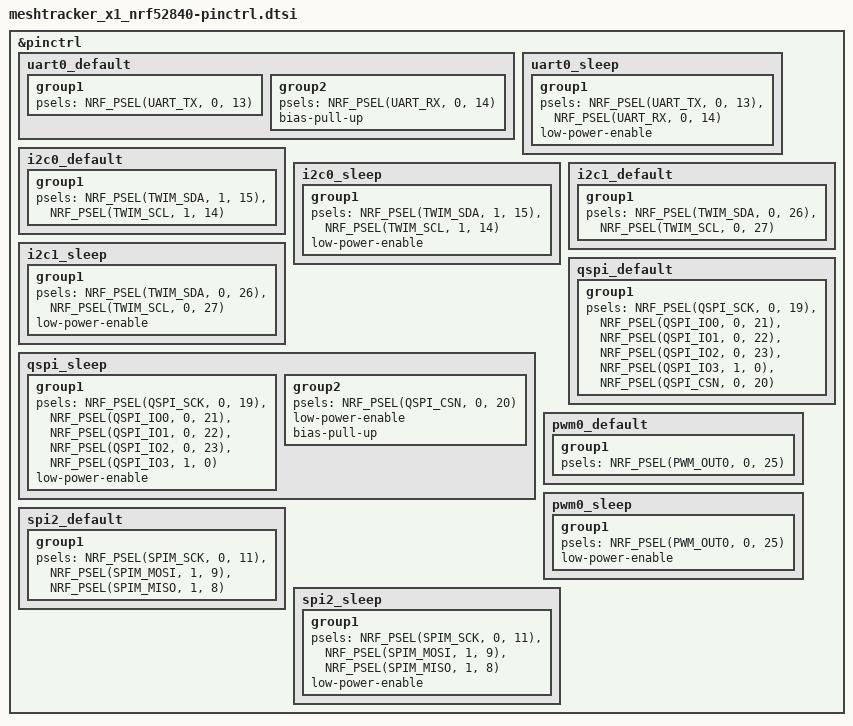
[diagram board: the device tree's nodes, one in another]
/*
 * Seeed SenseCAP MeshTracker X1 - Pin Control
 * Copyright (c) 2026 ZephCore
 * SPDX-License-Identifier: MIT
 */

&pinctrl {
	/* GNSS UART - Airoha dual-band L1+L5 at 115200 baud */
	uart0_default: uart0_default {
		group1 {
			psels = <NRF_PSEL(UART_TX, 0, 13)>;
		};
		group2 {
			psels = <NRF_PSEL(UART_RX, 0, 14)>;
			bias-pull-up;
		};
	};

	uart0_sleep: uart0_sleep {
		group1 {
			psels = <NRF_PSEL(UART_TX, 0, 13)>,
			        <NRF_PSEL(UART_RX, 0, 14)>;
			low-power-enable;
		};
	};

	/* I2C0 - SPA06 barometer + DRV2605L haptic driver */
	i2c0_default: i2c0_default {
		group1 {
			psels = <NRF_PSEL(TWIM_SDA, 1, 15)>,
			        <NRF_PSEL(TWIM_SCL, 1, 14)>;
		};
	};

	i2c0_sleep: i2c0_sleep {
		group1 {
			psels = <NRF_PSEL(TWIM_SDA, 1, 15)>,
			        <NRF_PSEL(TWIM_SCL, 1, 14)>;
			low-power-enable;
		};
	};

	/* I2C1 - YSN8900 RTC on its own bus */
	i2c1_default: i2c1_default {
		group1 {
			psels = <NRF_PSEL(TWIM_SDA, 0, 26)>,
			        <NRF_PSEL(TWIM_SCL, 0, 27)>;
		};
	};

	i2c1_sleep: i2c1_sleep {
		group1 {
			psels = <NRF_PSEL(TWIM_SDA, 0, 26)>,
			        <NRF_PSEL(TWIM_SCL, 0, 27)>;
			low-power-enable;
		};
	};

	/* QSPI - GD25Q64E 8MB flash */
	qspi_default: qspi_default {
		group1 {
			psels = <NRF_PSEL(QSPI_SCK, 0, 19)>,
				<NRF_PSEL(QSPI_IO0, 0, 21)>,
				<NRF_PSEL(QSPI_IO1, 0, 22)>,
				<NRF_PSEL(QSPI_IO2, 0, 23)>,
				<NRF_PSEL(QSPI_IO3, 1, 0)>,
				<NRF_PSEL(QSPI_CSN, 0, 20)>;
		};
	};

	qspi_sleep: qspi_sleep {
		group1 {
			psels = <NRF_PSEL(QSPI_SCK, 0, 19)>,
				<NRF_PSEL(QSPI_IO0, 0, 21)>,
				<NRF_PSEL(QSPI_IO1, 0, 22)>,
				<NRF_PSEL(QSPI_IO2, 0, 23)>,
				<NRF_PSEL(QSPI_IO3, 1, 0)>;
			low-power-enable;
		};
		group2 {
			psels = <NRF_PSEL(QSPI_CSN, 0, 20)>;
			low-power-enable;
			bias-pull-up;
		};
	};

	/* PWM0 for buzzer on P0.25 */
	pwm0_default: pwm0_default {
		group1 {
			psels = <NRF_PSEL(PWM_OUT0, 0, 25)>;
		};
	};

	pwm0_sleep: pwm0_sleep {
		group1 {
			psels = <NRF_PSEL(PWM_OUT0, 0, 25)>;
			low-power-enable;
		};
	};

	/* SPI2 for LR2021 (SPI1 shares its peripheral slot with I2C1) */
	spi2_default: spi2_default {
		group1 {
			psels = <NRF_PSEL(SPIM_SCK, 0, 11)>,
			        <NRF_PSEL(SPIM_MOSI, 1, 9)>,
			        <NRF_PSEL(SPIM_MISO, 1, 8)>;
		};
	};

	spi2_sleep: spi2_sleep {
		group1 {
			psels = <NRF_PSEL(SPIM_SCK, 0, 11)>,
			        <NRF_PSEL(SPIM_MOSI, 1, 9)>,
			        <NRF_PSEL(SPIM_MISO, 1, 8)>;
			low-power-enable;
		};
	};
};
